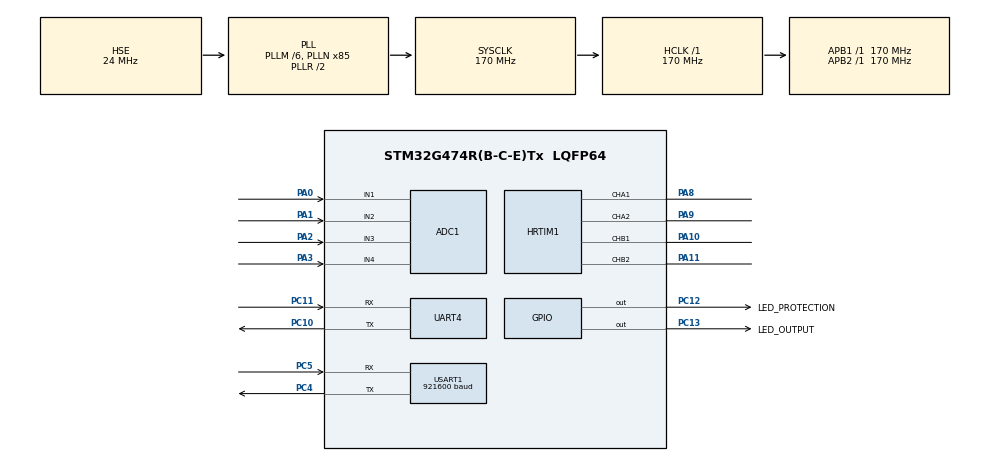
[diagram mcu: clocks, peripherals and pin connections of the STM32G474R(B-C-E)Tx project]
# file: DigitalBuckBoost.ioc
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ADC1.Channel-0\#ChannelRegularConversion=ADC_CHANNEL_1
ADC1.EnableInjectedConversion=ENABLE
ADC1.ExternalTrigInjecConv=ADC_EXTERNALTRIGINJEC_HRTIM_TRG2
ADC1.InjNumberOfConversion=2
ADC1.InjectedChannel-1\#ChannelInjectedConversion=ADC_CHANNEL_1
ADC1.InjectedChannel-2\#ChannelInjectedConversion=ADC_CHANNEL_2
ADC1.InjectedOffsetNumber-1\#ChannelInjectedConversion=ADC_OFFSET_NONE
ADC1.InjectedOffsetNumber-2\#ChannelInjectedConversion=ADC_OFFSET_NONE
ADC1.InjectedRank-1\#ChannelInjectedConversion=1
ADC1.InjectedRank-2\#ChannelInjectedConversion=2
ADC1.InjectedSamplingTime-1\#ChannelInjectedConversion=ADC_SAMPLETIME_12CYCLES_5
ADC1.InjectedSamplingTime-2\#ChannelInjectedConversion=ADC_SAMPLETIME_12CYCLES_5
ADC1.NbrOfConversionFlag=1
ADC1.OffsetNumber-0\#ChannelRegularConversion=ADC_OFFSET_NONE
ADC1.Rank-0\#ChannelRegularConversion=1
ADC1.Rank1_Channel=ADC_CHANNEL_1
ADC1.Rank2_Channel=ADC_CHANNEL_2
ADC1.Rank3_Channel=ADC_CHANNEL_3
ADC1.Rank4_Channel=ADC_CHANNEL_4
ADC1.SamplingTime-0\#ChannelRegularConversion=ADC_SAMPLETIME_2CYCLES_5
ADC1.master=1
Dma.Request0=USART1_TX
Dma.USART1_TX.0.Direction=DMA_MEMORY_TO_PERIPH
Dma.USART1_TX.0.EventEnable=DISABLE
Dma.USART1_TX.0.Instance=DMA1_Channel1
Dma.USART1_TX.0.MemDataAlignment=DMA_MDATAALIGN_BYTE
Dma.USART1_TX.0.MemInc=DMA_MINC_ENABLE
Dma.USART1_TX.0.Mode=DMA_NORMAL
Dma.USART1_TX.0.PeriphDataAlignment=DMA_PDATAALIGN_BYTE
Dma.USART1_TX.0.PeriphInc=DMA_PINC_DISABLE
Dma.USART1_TX.0.Polarity=HAL_DMAMUX_REQ_GEN_RISING
Dma.USART1_TX.0.Priority=DMA_PRIORITY_VERY_HIGH
Dma.USART1_TX.0.RequestNumber=1
Dma.USART1_TX.0.SignalID=NONE
Dma.USART1_TX.0.SyncEnable=DISABLE
Dma.USART1_TX.0.SyncPolarity=HAL_DMAMUX_SYNC_NO_EVENT
Dma.USART1_TX.0.SyncRequestNumber=1
Dma.USART1_TX.0.SyncSignalID=NONE
HRTIM1.ADCTrigger2_Source1=HRTIM_ADCTRIGGEREVENT24_MASTER_CMP1
HRTIM1.ADCTrigger_Id2=HRTIM_ADCTRIGGER_2
HRTIM1.ADCTrigger_Id4=__NULL
HRTIM1.CompareUnit1-MasterTimer=HRTIM_COMPAREUNIT_1
HRTIM1.CompareUnit1-Output_TA1TA2=HRTIM_COMPAREUNIT_1
HRTIM1.CompareUnit1-Output_TB1TB2=HRTIM_COMPAREUNIT_1
HRTIM1.CompareUnit3-Output_TA1TA2=HRTIM_COMPAREUNIT_3
HRTIM1.CompareUnit3-Output_TB1TB2=HRTIM_COMPAREUNIT_3
HRTIM1.CompareValue1-MasterTimer=680
HRTIM1.CompareValue1-Output_TA1TA2=13600
HRTIM1.CompareValue1-Output_TB1TB2=13600
HRTIM1.CompareValue3-Output_TA1TA2=27200
HRTIM1.CompareValue3-Output_TB1TB2=27200
HRTIM1.DeadTimeInsertion-Output_TA1TA2=HRTIM_TIMDEADTIMEINSERTION_ENABLED
HRTIM1.DeadTimeInsertion-Output_TB1TB2=HRTIM_TIMDEADTIMEINSERTION_ENABLED
HRTIM1.FallingValue-Output_TA1TA2=10
HRTIM1.FallingValue-Output_TB1TB2=10
HRTIM1.InterruptRequests1_Master=HRTIM_MASTER_IT_MREP
HRTIM1.NumberADCTriggerSource2=1
HRTIM1.NumberInterruptRequests_Master-MasterTimer=1
HRTIM1.NumberResetSource1-Output_TA1TA2=1
HRTIM1.NumberResetSource1-Output_TB1TB2=1
HRTIM1.NumberResetSource2_TB=0
HRTIM1.NumberResetTrigger-Output_TA1TA2=1
HRTIM1.NumberResetTrigger-Output_TB1TB2=1
HRTIM1.NumberSetSource1-Output_TA1TA2=1
HRTIM1.NumberSetSource1-Output_TB1TB2=1
HRTIM1.NumberSetSource2_TB=0
HRTIM1.Periode_MASTER=27200
HRTIM1.Periode_TA=27200
HRTIM1.Periode_TB=27200
HRTIM1.Polarity2-Output_TB1TB2=HRTIM_OUTPUTPOLARITY_HIGH
HRTIM1.PreloadEnable-MasterTimer=HRTIM_PRELOAD_ENABLED
HRTIM1.PreloadEnable-Output_TA1TA2=HRTIM_PRELOAD_ENABLED
HRTIM1.PreloadEnable-Output_TB1TB2=HRTIM_PRELOAD_ENABLED
HRTIM1.PrescalerDead-Output_TA1TA2=HRTIM_TIMDEADTIME_PRESCALERRATIO_DIV1
HRTIM1.PrescalerDead-Output_TB1TB2=HRTIM_TIMDEADTIME_PRESCALERRATIO_DIV1
HRTIM1.RepetitionUpdate-MasterTimer=HRTIM_UPDATEONREPETITION_ENABLED
HRTIM1.RepetitionUpdate-Output_TA1TA2=HRTIM_UPDATEONREPETITION_ENABLED
HRTIM1.RepetitionUpdate-Output_TB1TB2=HRTIM_UPDATEONREPETITION_ENABLED
HRTIM1.ResetOutput1_Source1-Output_TA1TA2=HRTIM_OUTPUTRESET_TIMCMP1
HRTIM1.ResetOutput1_Source1-Output_TB1TB2=HRTIM_OUTPUTRESET_TIMCMP1
HRTIM1.ResetTrigger1-Output_TA1TA2=HRTIM_TIMRESETTRIGGER_MASTER_PER
HRTIM1.ResetTrigger1-Output_TB1TB2=HRTIM_TIMRESETTRIGGER_MASTER_PER
HRTIM1.RisingValue-Output_TA1TA2=10
HRTIM1.RisingValue-Output_TB1TB2=10
HRTIM1.SetOutput1_Source1-Output_TA1TA2=HRTIM_OUTPUTSET_TIMCMP3
HRTIM1.SetOutput1_Source1-Output_TB1TB2=HRTIM_OUTPUTSET_TIMCMP3
Mcu.Family=STM32G4
Mcu.Name=STM32G474R(B-C-E)Tx
Mcu.Package=LQFP64
NVIC.ADC1_2_IRQn=true\:1\:0\:true\:false\:true\:true\:true\:true
NVIC.DMA1_Channel1_IRQn=true\:0\:0\:false\:false\:true\:true\:true\:true
NVIC.HRTIM1_Master_IRQn=true\:2\:0\:true\:false\:true\:true\:true\:true
NVIC.PriorityGroup=NVIC_PRIORITYGROUP_4
NVIC.USART1_IRQn=true\:0\:0\:false\:false\:true\:true\:true\:true
PA0.Mode=IN1-Single-Ended
PA0.Signal=ADC1_IN1
PA1.Mode=IN2-Single-Ended
PA1.Signal=ADC1_IN2
PA10.Mode=Output_TB1TB2
PA10.Signal=HRTIM1_CHB1
PA11.Mode=Output_TB1TB2
PA11.Signal=HRTIM1_CHB2
PA13.Mode=Serial_Wire
PA13.Signal=SYS_JTMS-SWDIO
PA14.Mode=Serial_Wire
PA14.Signal=SYS_JTCK-SWCLK
PA2.Mode=IN3-Single-Ended
PA2.Signal=ADC1_IN3
PA3.Mode=IN4-Single-Ended
PA3.Signal=ADC1_IN4
PA8.Mode=Output_TA1TA2
PA8.Signal=HRTIM1_CHA1
PA9.Mode=Output_TA1TA2
PA9.Signal=HRTIM1_CHA2
PC10.Mode=Asynchronous
PC10.Signal=UART4_TX
PC11.Mode=Asynchronous
PC11.Signal=UART4_RX
PC12.GPIO_Label=LED_PROTECTION
PC12.PinState=GPIO_PIN_SET
PC12.Signal=GPIO_Output
PC13.GPIO_Label=LED_OUTPUT
PC13.PinState=GPIO_PIN_SET
PC13.Signal=GPIO_Output
PC4.Mode=Asynchronous
PC4.Signal=USART1_TX
PC5.Mode=Asynchronous
PC5.Signal=USART1_RX
PF0-OSC_IN.Mode=HSE-External-Oscillator
PF0-OSC_IN.Signal=RCC_OSC_IN
PF1-OSC_OUT.Mode=HSE-External-Oscillator
PF1-OSC_OUT.Signal=RCC_OSC_OUT
ProjectManager.HeapSize=0x200
ProjectManager.StackSize=0x400
ProjectManager.TargetToolchain=MDK-ARM V5.32
RCC.ADC12Freq_Value=170000000
RCC.ADC345Freq_Value=170000000
RCC.AHBFreq_Value=170000000
RCC.APB1Freq_Value=170000000
RCC.APB1TimFreq_Value=170000000
RCC.APB2Freq_Value=170000000
RCC.APB2TimFreq_Value=170000000
RCC.CortexFreq_Value=170000000
RCC.EXTERNAL_CLOCK_VALUE=12288000
RCC.HCLKFreq_Value=170000000
RCC.HSE_VALUE=24000000
RCC.HSI48_VALUE=48000000
RCC.HSI_VALUE=16000000
RCC.LSE_VALUE=32768
RCC.PLLM=RCC_PLLM_DIV6
RCC.PLLN=85
RCC.PLLSourceVirtual=RCC_PLLSOURCE_HSE
RCC.SYSCLKFreq_VALUE=170000000
RCC.SYSCLKSource=RCC_SYSCLKSOURCE_PLLCLK
RCC.USBFreq_Value=170000000
RCC.VCOOutputFreq_Value=340000000
USART1.BaudRate=921600
USART1.VirtualMode-Asynchronous=VM_ASYNC
VP_HRTIM1_VS_hrtimMasterTimerNoOutput.Mode=MasterTimer
VP_SYS_VS_DBSignals.Mode=DisableDeadBatterySignals
board=custom

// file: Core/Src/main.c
/* USER CODE BEGIN Header */
/**
  ******************************************************************************
  * @file           : main.c
  * @brief          : Main program body
  ******************************************************************************
  * @attention
  *
  * Copyright (c) 2024 STMicroelectronics.
  * All rights reserved.
  *
  * This software is licensed under terms that can be found in the LICENSE file
  * in the root directory of this software component.
  * If no LICENSE file comes with this software, it is provided AS-IS.
  *
  ******************************************************************************
  */
/* USER CODE END Header */
#include "main.h"
#include "adc.h"
#include "dma.h"
#include "hrtim.h"
#include "usart.h"
#include "gpio.h"

/* USER CODE BEGIN Includes */
#include "application.h"
/* USER CODE END Includes */

void SystemClock_Config(void);

int main(void)
{

  /* MCU Configuration--------------------------------------------------------*/

  /* Reset of all peripherals, Initializes the Flash interface and the Systick. */
  HAL_Init();

  /* Configure the system clock */
  SystemClock_Config();

  /* Initialize all configured peripherals */
  MX_GPIO_Init();
  MX_DMA_Init();
  MX_HRTIM1_Init();
  MX_USART1_UART_Init();
  MX_ADC1_Init();
  MX_UART4_Init();
  /* USER CODE BEGIN 2 */
  APP_Init();
  /* USER CODE END 2 */

  /* Infinite loop */
  /* USER CODE BEGIN WHILE */
  while (1)
  {
    APP_MainLoop();
    /* USER CODE END WHILE */

  }
}

void SystemClock_Config(void)
{
  RCC_OscInitTypeDef RCC_OscInitStruct = {0};
  RCC_ClkInitTypeDef RCC_ClkInitStruct = {0};

  /** Configure the main internal regulator output voltage
  */
  HAL_PWREx_ControlVoltageScaling(PWR_REGULATOR_VOLTAGE_SCALE1_BOOST);

  /** Initializes the RCC Oscillators according to the specified parameters
  * in the RCC_OscInitTypeDef structure.
  */
  RCC_OscInitStruct.OscillatorType = RCC_OSCILLATORTYPE_HSE;
  RCC_OscInitStruct.HSEState = RCC_HSE_ON;
  RCC_OscInitStruct.PLL.PLLState = RCC_PLL_ON;
  RCC_OscInitStruct.PLL.PLLSource = RCC_PLLSOURCE_HSE;
  RCC_OscInitStruct.PLL.PLLM = RCC_PLLM_DIV6;
  RCC_OscInitStruct.PLL.PLLN = 85;
  RCC_OscInitStruct.PLL.PLLP = RCC_PLLP_DIV2;
  RCC_OscInitStruct.PLL.PLLQ = RCC_PLLQ_DIV2;
  RCC_OscInitStruct.PLL.PLLR = RCC_PLLR_DIV2;
  if (HAL_RCC_OscConfig(&RCC_OscInitStruct) != HAL_OK)
  {
    Error_Handler();
  }

  /** Initializes the CPU, AHB and APB buses clocks
  */
  RCC_ClkInitStruct.ClockType = RCC_CLOCKTYPE_HCLK|RCC_CLOCKTYPE_SYSCLK
                              |RCC_CLOCKTYPE_PCLK1|RCC_CLOCKTYPE_PCLK2;
  RCC_ClkInitStruct.SYSCLKSource = RCC_SYSCLKSOURCE_PLLCLK;
  RCC_ClkInitStruct.AHBCLKDivider = RCC_SYSCLK_DIV1;
  RCC_ClkInitStruct.APB1CLKDivider = RCC_HCLK_DIV1;
  RCC_ClkInitStruct.APB2CLKDivider = RCC_HCLK_DIV1;

  if (HAL_RCC_ClockConfig(&RCC_ClkInitStruct, FLASH_LATENCY_4) != HAL_OK)
  {
    Error_Handler();
  }
}

void Error_Handler(void)
{
  __disable_irq();
  while (1)
  {
  }
}
